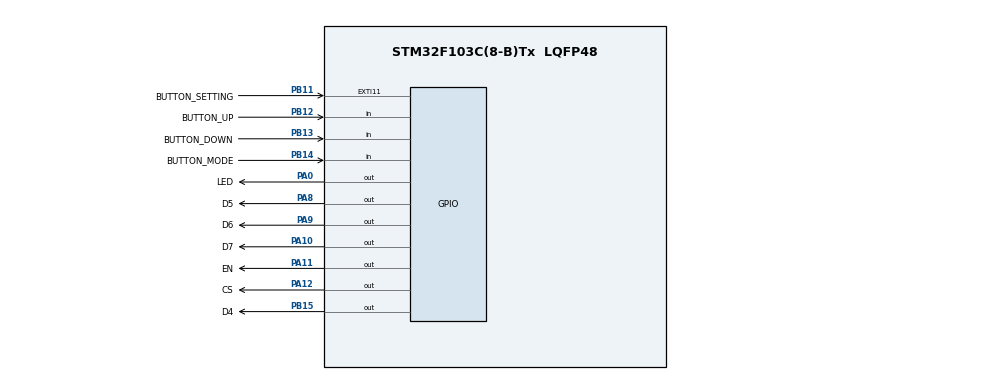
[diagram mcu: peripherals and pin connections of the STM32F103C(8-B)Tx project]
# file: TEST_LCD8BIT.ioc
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Mcu.Family=STM32F1
Mcu.Name=STM32F103C(8-B)Tx
Mcu.Package=LQFP48
NVIC.EXTI15_10_IRQn=true\:0\:0\:false\:false\:true\:true\:true\:true
NVIC.PriorityGroup=NVIC_PRIORITYGROUP_4
PA0-WKUP.GPIO_Label=LED
PA0-WKUP.Signal=GPIO_Output
PA10.GPIO_Label=D7
PA10.Signal=GPIO_Output
PA11.GPIO_Label=EN
PA11.Signal=GPIO_Output
PA12.GPIO_Label=CS
PA12.Signal=GPIO_Output
PA13.Mode=Serial_Wire
PA13.Signal=SYS_JTMS-SWDIO
PA14.Mode=Serial_Wire
PA14.Signal=SYS_JTCK-SWCLK
PA8.GPIO_Label=D5
PA8.Signal=GPIO_Output
PA9.GPIO_Label=D6
PA9.Signal=GPIO_Output
PB11.GPIO_Label=BUTTON_SETTING
PB11.GPIO_ModeDefaultEXTI=GPIO_MODE_IT_FALLING
PB11.GPIO_PuPd=GPIO_PULLUP
PB11.Signal=GPXTI11
PB12.GPIO_Label=BUTTON_UP
PB12.GPIO_PuPd=GPIO_PULLUP
PB12.Signal=GPIO_Input
PB13.GPIO_Label=BUTTON_DOWN
PB13.GPIO_PuPd=GPIO_PULLUP
PB13.Signal=GPIO_Input
PB14.GPIO_Label=BUTTON_MODE
PB14.GPIO_PuPd=GPIO_PULLUP
PB14.Signal=GPIO_Input
PB15.GPIO_Label=D4
PB15.Signal=GPIO_Output
ProjectManager.HeapSize=0x200
ProjectManager.StackSize=0x400
ProjectManager.TargetToolchain=MDK-ARM V5.32
RCC.APB1Freq_Value=8000000
RCC.APB2Freq_Value=8000000
board=custom

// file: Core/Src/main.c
/* USER CODE BEGIN Header */
/**
  ******************************************************************************
  * @file           : main.c
  * @brief          : Main program body
  ******************************************************************************
  * @attention
  *
  * Copyright (c) 2023 STMicroelectronics.
  * All rights reserved.
  *
  * This software is licensed under terms that can be found in the LICENSE file
  * in the root directory of this software component.
  * If no LICENSE file comes with this software, it is provided AS-IS.
  *
  ******************************************************************************
  */
/* USER CODE END Header */
#include "main.h"

/* USER CODE BEGIN Includes */

#include "CLCD.h"
#include "BUTTON.h"
#include "Setpoint_Interrupt.h"
#include <stdio.h>
/* USER CODE END Includes */

/* USER CODE BEGIN PV */
CLCD_Name LCD1;
Set_Button Button;
Setpoint Data;
Mode_State currentMode;
int clickCount;
/* USER CODE END PV */

void SystemClock_Config(void);
static void MX_GPIO_Init(void);

int main(void)
{

  /* MCU Configuration--------------------------------------------------------*/

  /* Reset of all peripherals, Initializes the Flash interface and the Systick. */
  HAL_Init();

  /* Configure the system clock */
  SystemClock_Config();

  /* Initialize all configured peripherals */
  MX_GPIO_Init();
  /* USER CODE BEGIN 2 */
  BUTTON_Init(&Button.DOWN, BUTTON_DOWN_GPIO_Port, BUTTON_DOWN_Pin);
	BUTTON_Init(&Button.UP, BUTTON_UP_GPIO_Port, BUTTON_UP_Pin);
	BUTTON_Init(&Button.MODE, BUTTON_MODE_GPIO_Port, BUTTON_MODE_Pin);
	BUTTON_Init(&Button.SETTING, BUTTON_SETTING_GPIO_Port, BUTTON_SETTING_Pin);
	CLCD_4BIT_Init(&LCD1, 16,2, CS_GPIO_Port,CS_Pin ,EN_GPIO_Port,EN_Pin ,D4_GPIO_Port,D4_Pin, D5_GPIO_Port,D5_Pin,D6_GPIO_Port,D6_Pin,D7_GPIO_Port, D7_Pin);
  /* USER CODE END 2 */

  /* Infinite loop */
  while (1)
  {
		Data = Setpoint_Interrupt_Mode(&Data, &Button, &LCD1, currentMode, &clickCount);
  }
}

void SystemClock_Config(void)
{
  RCC_OscInitTypeDef RCC_OscInitStruct = {0};
  RCC_ClkInitTypeDef RCC_ClkInitStruct = {0};

  /** Initializes the RCC Oscillators according to the specified parameters
  * in the RCC_OscInitTypeDef structure.
  */
  RCC_OscInitStruct.OscillatorType = RCC_OSCILLATORTYPE_HSI;
  RCC_OscInitStruct.HSIState = RCC_HSI_ON;
  RCC_OscInitStruct.HSICalibrationValue = RCC_HSICALIBRATION_DEFAULT;
  RCC_OscInitStruct.PLL.PLLState = RCC_PLL_NONE;
  if (HAL_RCC_OscConfig(&RCC_OscInitStruct) != HAL_OK)
  {
    Error_Handler();
  }

  /** Initializes the CPU, AHB and APB buses clocks
  */
  RCC_ClkInitStruct.ClockType = RCC_CLOCKTYPE_HCLK|RCC_CLOCKTYPE_SYSCLK
                              |RCC_CLOCKTYPE_PCLK1|RCC_CLOCKTYPE_PCLK2;
  RCC_ClkInitStruct.SYSCLKSource = RCC_SYSCLKSOURCE_HSI;
  RCC_ClkInitStruct.AHBCLKDivider = RCC_SYSCLK_DIV1;
  RCC_ClkInitStruct.APB1CLKDivider = RCC_HCLK_DIV1;
  RCC_ClkInitStruct.APB2CLKDivider = RCC_HCLK_DIV1;

  if (HAL_RCC_ClockConfig(&RCC_ClkInitStruct, FLASH_LATENCY_0) != HAL_OK)
  {
    Error_Handler();
  }
}

static void MX_GPIO_Init(void)
{
  GPIO_InitTypeDef GPIO_InitStruct = {0};

  /* GPIO Ports Clock Enable */
  __HAL_RCC_GPIOA_CLK_ENABLE();
  __HAL_RCC_GPIOB_CLK_ENABLE();

  /*Configure GPIO pin Output Level */
  HAL_GPIO_WritePin(GPIOA, LED_Pin|D5_Pin|D6_Pin|D7_Pin
                          |EN_Pin|CS_Pin, GPIO_PIN_RESET);

  /*Configure GPIO pin Output Level */
  HAL_GPIO_WritePin(D4_GPIO_Port, D4_Pin, GPIO_PIN_RESET);

  /*Configure GPIO pins : LED_Pin D5_Pin D6_Pin D7_Pin
                           EN_Pin CS_Pin */
  GPIO_InitStruct.Pin = LED_Pin|D5_Pin|D6_Pin|D7_Pin
                          |EN_Pin|CS_Pin;
  GPIO_InitStruct.Mode = GPIO_MODE_OUTPUT_PP;
  GPIO_InitStruct.Pull = GPIO_NOPULL;
  GPIO_InitStruct.Speed = GPIO_SPEED_FREQ_LOW;
  HAL_GPIO_Init(GPIOA, &GPIO_InitStruct);

  /*Configure GPIO pin : BUTTON_SETTING_Pin */
  GPIO_InitStruct.Pin = BUTTON_SETTING_Pin;
  GPIO_InitStruct.Mode = GPIO_MODE_IT_FALLING;
  GPIO_InitStruct.Pull = GPIO_PULLUP;
  HAL_GPIO_Init(BUTTON_SETTING_GPIO_Port, &GPIO_InitStruct);

  /*Configure GPIO pins : BUTTON_UP_Pin BUTTON_DOWN_Pin BUTTON_MODE_Pin */
  GPIO_InitStruct.Pin = BUTTON_UP_Pin|BUTTON_DOWN_Pin|BUTTON_MODE_Pin;
  GPIO_InitStruct.Mode = GPIO_MODE_INPUT;
  GPIO_InitStruct.Pull = GPIO_PULLUP;
  HAL_GPIO_Init(GPIOB, &GPIO_InitStruct);

  /*Configure GPIO pin : D4_Pin */
  GPIO_InitStruct.Pin = D4_Pin;
  GPIO_InitStruct.Mode = GPIO_MODE_OUTPUT_PP;
  GPIO_InitStruct.Pull = GPIO_NOPULL;
  GPIO_InitStruct.Speed = GPIO_SPEED_FREQ_LOW;
  HAL_GPIO_Init(D4_GPIO_Port, &GPIO_InitStruct);

  /* EXTI interrupt init*/
  HAL_NVIC_SetPriority(EXTI15_10_IRQn, 0, 0);
  HAL_NVIC_EnableIRQ(EXTI15_10_IRQn);

}

void Error_Handler(void)
{
  __disable_irq();
  while (1)
  {
  }
}
